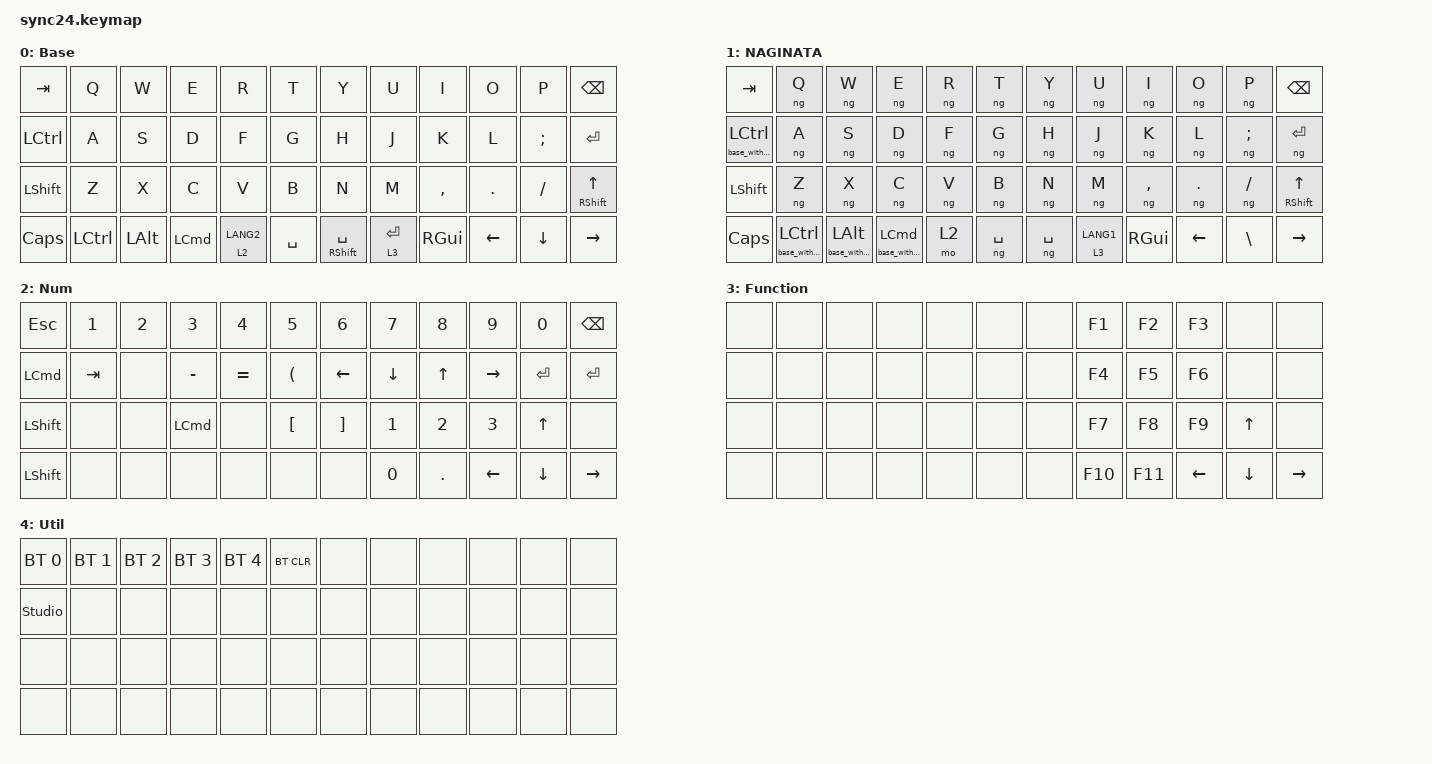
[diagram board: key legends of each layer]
#define ZMK_BEHAVIORS_OMIT_KT

#undef ZMK_BEHAVIORS_KEEP_ALL

#define ZMK_BEHAVIORS_KEEP_SK
#define ZMK_BEHAVIORS_KEEP_MT
#define ZMK_BEHAVIORS_KEEP_KT

#include <behaviors.dtsi>
#include <behaviors/naginata.dtsi> // naginata

#include <dt-bindings/zmk/keys.h>
#include <dt-bindings/zmk/bt.h>
#include <dt-bindings/zmk/outputs.h>

/ {
    macros {
        ng_on: ng_on {
            compatible = "zmk,behavior-macro";
            #binding-cells = <0>;
            bindings
                = <&macro_tap &kp LANGUAGE_1 &kp INTERNATIONAL_4 &to 1> //薙刀式レイヤーの1へ
                ;
        };
        ng_off: ng_off {
            compatible = "zmk,behavior-macro";
            #binding-cells = <0>;
            bindings
                = <&macro_tap &kp LANGUAGE_2 &kp INTERNATIONAL_5 &to 0>
                ;
        };
        base_with_mod: base_with_mod { //薙刀式レイヤーのキーマップに配置する zmkstudioも対応
            compatible = "zmk,behavior-macro-one-param";
            wait-ms = <0>;
            tap-ms = <0>;
            #binding-cells = <1>;
            bindings
                = <&macro_press &tog 1 > //レイヤー0に移動する。なぜか1でいいらしい。
                , <&macro_param_1to1>
                , <&macro_press &kp MACRO_PLACEHOLDER> //登録した修飾キーの入力
                , <&macro_pause_for_release>
                , <&macro_param_1to1>
                , <&macro_release &kp MACRO_PLACEHOLDER> //薙刀レイヤーに戻る
                , <&macro_press &tog 1 >
                ;
        };
        yt_skip_by_next_back: yt_skip_by_next_back {
            compatible = "zmk,behavior-macro";
            #binding-cells = <0>;
            wait-ms = <60>;
            tap-ms = <30>;
            bindings 
                = <&macro_press &kp LSHFT>
                , <&macro_tap &kp N>
                , <&macro_release &kp LSHFT>
                , <&macro_wait_time 600>
                , <&macro_press &kp LGUI>
                , <&macro_tap &kp LBKT>
                , <&macro_release &kp LGUI>
                , <&macro_wait_time 60>
                ;
        };
        yt_skip_safari: yt_skip_safari {
            compatible = "zmk,behavior-macro";
            #binding-cells = <0>;
            wait-ms = <120>;
            tap-ms = <40>;
            bindings 
                = <&macro_press &kp LALT>
                , <&macro_tap &kp TAB>
                , <&macro_tap &kp TAB>
                , <&macro_tap &kp TAB>
                , <&macro_tap &kp TAB>
                , <&macro_release &kp LALT>
                , <&macro_tap &kp ENTER>
                ;
        };
    };

    combos {
        compatible = "zmk,combos";

        combo_ng_on {
            timeout-ms = <300>;
            key-positions = <18 19>; // H, Jのキー位置に書き換えてください
            bindings = <&ng_on>;
            layers = <0>; // デフォルトレイヤーが0の前提
        };
        combo_ng_off {
            timeout-ms = <300>;
            key-positions = <16 17>; // F, Gのキー位置に書き換えてください
            bindings = <&ng_off>;
            layers = <0 1>; // デフォルトレイヤーが0、薙刀式レイヤーが1の前提、4に書き換え、で1へ
        };

        combo_return {
            timeout-ms = <50>;
            key-positions = <28 31>; // 全てのレイヤーで同時押しの改行。VとMのキー位置に書き換えてください
            bindings = <&kp RET>;
        };

//        combo_us {
//            timeout-ms = <50>;
//            key-positions = <16 17>;
//            bindings = <&kp LANG2>;
//        };
//
//        combo_kana {
//            timeout-ms = <50>;
//            key-positions = <18 19>;
//            bindings = <&kp LANG1>;
//        };

        combo_util {
            timeout-ms = <50>;
            key-positions = <36 37>;
            bindings = <&mo 4>; //薙刀式レイヤーが1になったので、3から4へ
        };
    };

    keymap {
        compatible = "zmk,keymap";

// ▄▄▄▄▄▄▄▄▄▄▄▄▄▄▄▄▄▄▄▄▄▄▄▄▄▄▄▄▄▄▄▄▄▄▄▄▄▄▄▄▄▄▄▄▄▄▄▄▄▄▄▄▄▄▄▄▄▄▄▄▄▄▄▄▄▄▄▄▄▄▄▄▄▄▄▄▄▄▄▄▄▄▄▄▄▄▄▄▄▄▄▄▄▄▄▄▄▄▄▄▄▄▄▄▄▄▄▄▄▄▄▄▄▄▄▄▄▄▄▄▄▄▄▄▄▄▄▄▄▄▄▄▄▄▄▄▄▄▄▄▄▄▄▄▄▄▄▄▄
        base {
            display-name = "Base";
            bindings = <

// ╷           ╷           ╷           ╷           ╷           ╷           ╷   ╷           ╷           ╷           ╷           ╷           ╷           ╷
    &kp TAB    &kp Q       &kp W       &kp E       &kp R       &kp T           &kp Y       &kp U       &kp I       &kp O       &kp P         &kp BACKSPACE 
    &kp LCTRL  &kp A       &kp S       &kp D       &kp F       &kp G           &kp H       &kp J       &kp K       &kp L       &kp SEMICOLON &kp RET
    &kp LSHFT  &kp Z       &kp X       &kp C       &kp V       &kp B           &kp N       &kp M       &kp COMMA   &kp DOT     &kp FSLH      &mt RSHFT UP 
    &kp CAPS   &kp LCTRL   &kp LALT    &kp LCMD    &lt 2 LANG2  &kp SPACE      &mt RSHFT SPACE   &lt 3 RET   &kp RGUI    &kp LEFT    &kp DOWN_ARROW    &kp RIGHT

            >;
        };

// ▄▄▄▄▄▄▄▄▄▄▄▄▄▄▄▄▄▄▄▄▄▄▄▄▄▄▄▄▄▄▄▄▄▄▄▄▄▄▄▄▄▄▄▄▄▄▄▄▄▄▄▄▄▄▄▄▄▄▄▄▄▄▄▄▄▄▄▄▄▄▄▄▄▄▄▄▄▄▄▄▄▄▄▄▄▄▄▄▄▄▄▄▄▄▄▄▄▄▄▄▄▄▄▄▄▄▄▄▄▄▄▄▄▄▄▄▄▄▄▄▄▄▄▄▄▄▄▄▄▄▄▄▄▄▄▄▄▄▄▄▄▄▄▄▄▄▄▄▄
        extra1 {
//          status = "reserved";
            display-name = "NAGINATA";
            bindings = <

// ╷           ╷           ╷           ╷           ╷           ╷           ╷   ╷           ╷           ╷           ╷           ╷           ╷           ╷
    &kp TAB    &ng Q       &ng W       &ng E       &ng R       &ng T           &ng Y       &ng U       &ng I       &ng O       &ng P         &kp BACKSPACE 
    &base_with_mod LCTRL  &ng A       &ng S       &ng D       &ng F       &ng G           &ng H       &ng J       &ng K       &ng L       &ng SEMI      &ng ENTER
    &kp LSHFT  &ng Z       &ng X       &ng C       &ng V       &ng B           &ng N       &ng M       &ng COMMA   &ng DOT     &ng SLASH      &mt RSHIFT UP
    &kp CAPS   &base_with_mod LCTRL   &base_with_mod LALT    &base_with_mod LCMD    &mo 2       &ng SPACE       &ng SPACE   &lt 3 LANG1 &kp RGUI    &kp LEFT    &kp BSLH      &kp RIGHT
            
            >;
        };

// ▄▄▄▄▄▄▄▄▄▄▄▄▄▄▄▄▄▄▄▄▄▄▄▄▄▄▄▄▄▄▄▄▄▄▄▄▄▄▄▄▄▄▄▄▄▄▄▄▄▄▄▄▄▄▄▄▄▄▄▄▄▄▄▄▄▄▄▄▄▄▄▄▄▄▄▄▄▄▄▄▄▄▄▄▄▄▄▄▄▄▄▄▄▄▄▄▄▄▄▄▄▄▄▄▄▄▄▄▄▄▄▄▄▄▄▄▄▄▄▄▄▄▄▄▄▄▄▄▄▄▄▄▄▄▄▄▄▄▄▄▄▄▄▄▄▄▄▄▄
        num {
            display-name = "Num";
            bindings = <

// ╷           ╷           ╷           ╷           ╷           ╷           ╷   ╷           ╷           ╷           ╷           ╷           ╷           ╷
    &kp ESC     &kp N1      &kp N2      &kp N3      &kp N4      &kp N5          &kp N6      &kp N7      &kp N8      &kp N9         &kp N0         &kp BACKSPACE 
    &kp LCMD    &kp TAB     &none       &kp MINUS   &kp EQUAL   &kp LPAR        &kp LEFT    &kp DOWN    &kp UP      &kp RIGHT      &kp RET        &kp RET
    &kp LSHFT   &none       &none       &kp LCMD    &none       &kp LBKT        &kp RBKT    &kp N1      &kp N2      &kp N3         &kp UP_ARROW   &none
    &kp LSHFT   &none       &none       &none       &none       &none           &none       &kp N0      &kp DOT     &kp LEFT_ARROW &kp DOWN_ARROW &kp RIGHT_ARROW

            >;
        };

// ▄▄▄▄▄▄▄▄▄▄▄▄▄▄▄▄▄▄▄▄▄▄▄▄▄▄▄▄▄▄▄▄▄▄▄▄▄▄▄▄▄▄▄▄▄▄▄▄▄▄▄▄▄▄▄▄▄▄▄▄▄▄▄▄▄▄▄▄▄▄▄▄▄▄▄▄▄▄▄▄▄▄▄▄▄▄▄▄▄▄▄▄▄▄▄▄▄▄▄▄▄▄▄▄▄▄▄▄▄▄▄▄▄▄▄▄▄▄▄▄▄▄▄▄▄▄▄▄▄▄▄▄▄▄▄▄▄▄▄▄▄▄▄▄▄▄▄▄▄
        function {
            display-name = "Function";
            bindings = <

// ╷           ╷           ╷           ╷           ╷           ╷           ╷   ╷           ╷           ╷           ╷           ╷           ╷           ╷
    &none       &none       &none       &none       &none       &none           &none       &kp F1      &kp F2      &kp F3       &none      &none
    &none       &none       &none       &none       &none       &none           &none       &kp F4      &kp F5      &kp F6       &none      &none
    &none       &none       &none       &none       &none       &none           &none       &kp F7      &kp F8      &kp F9       &kp UP     &none
    &none       &none       &none       &none       &none       &none           &none       &kp F10     &kp F11     &kp LEFT     &kp DOWN   &kp RIGHT
            
            >;
        };


// ▄▄▄▄▄▄▄▄▄▄▄▄▄▄▄▄▄▄▄▄▄▄▄▄▄▄▄▄▄▄▄▄▄▄▄▄▄▄▄▄▄▄▄▄▄▄▄▄▄▄▄▄▄▄▄▄▄▄▄▄▄▄▄▄▄▄▄▄▄▄▄▄▄▄▄▄▄▄▄▄▄▄▄▄▄▄▄▄▄▄▄▄▄▄▄▄▄▄▄▄▄▄▄▄▄▄▄▄▄▄▄▄▄▄▄▄▄▄▄▄▄▄▄▄▄▄▄▄▄▄▄▄▄▄▄▄▄▄▄▄▄▄▄▄▄▄▄▄▄
        util {
            display-name = "Util";
            bindings = <

// ╷               ╷           ╷           ╷           ╷           ╷           ╷   ╷           ╷           ╷           ╷           ╷           ╷           ╷
    &bt BT_SEL 0    &bt BT_SEL 1&bt BT_SEL 2&bt BT_SEL 3&bt BT_SEL 4&bt BT_CLR      &none       &none       &none       &none       &none       &none
    &studio_unlock  &none       &none       &none       &none       &none           &none       &none       &none       &none       &none       &none
    &none           &none       &none       &none       &none       &none           &none       &none       &none       &none       &none       &none
    &none           &none       &none       &none       &none       &none           &none       &none       &none       &none       &none       &none
            
            >;
        };


// ▄▄▄▄▄▄▄▄▄▄▄▄▄▄▄▄▄▄▄▄▄▄▄▄▄▄▄▄▄▄▄▄▄▄▄▄▄▄▄▄▄▄▄▄▄▄▄▄▄▄▄▄▄▄▄▄▄▄▄▄▄▄▄▄▄▄▄▄▄▄▄▄▄▄▄▄▄▄▄▄▄▄▄▄▄▄▄▄▄▄▄▄▄▄▄▄▄▄▄▄▄▄▄▄▄▄▄▄▄▄▄▄▄▄▄▄▄▄▄▄▄▄▄▄▄▄▄▄▄▄▄▄▄▄▄▄▄▄▄▄▄▄▄▄▄▄▄▄▄
        extra2 {
            status = "reserved";
            bindings = <

// ╷           ╷           ╷           ╷           ╷           ╷           ╷   ╷           ╷           ╷           ╷           ╷           ╷           ╷
    &none       &none       &none       &none       &none       &none           &none       &none       &none       &none       &none       &none
    &none       &none       &none       &none       &none       &none           &none       &none       &none       &none       &none       &none
    &none       &none       &none       &none       &none       &none           &none       &none       &none       &none       &none       &none
    &none       &none       &none       &none       &none       &none           &none       &none       &none       &none       &none       &none
            
            >;
        };

    };
};
